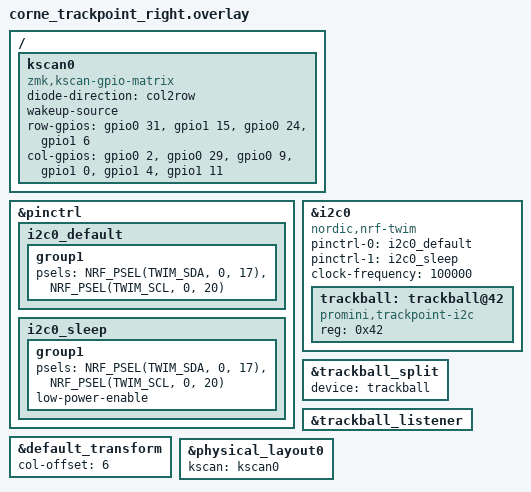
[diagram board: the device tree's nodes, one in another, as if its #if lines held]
#include "corne_trackpoint.dtsi"

&pinctrl {
    i2c0_default: i2c0_default {
        group1 {
            psels = <NRF_PSEL(TWIM_SDA, 0, 17)>,
                    <NRF_PSEL(TWIM_SCL, 0, 20)>;
        };
    };
    i2c0_sleep: i2c0_sleep {
        group1 {
            psels = <NRF_PSEL(TWIM_SDA, 0, 17)>,
                    <NRF_PSEL(TWIM_SCL, 0, 20)>;
            low-power-enable;
        };
    };
};

&i2c0 {
    compatible = "nordic,nrf-twim";
    status = "okay";
    pinctrl-0 = <&i2c0_default>;
    pinctrl-1 = <&i2c0_sleep>;
    pinctrl-names = "default", "sleep";
    clock-frequency = <100000>;

    trackball: trackball@42 {
        compatible = "promini,trackpoint-i2c";
        reg = <0x42>;
    };
};

#if defined(CONFIG_ZMK_SPLIT_ROLE_PERIPHERAL) && CONFIG_ZMK_SPLIT_ROLE_PERIPHERAL
/* Peripheral: split forwards trackball data to dongle */
&trackball_split {
    device = <&trackball>;
};
&trackball_listener {
    status = "okay";
};
#else
/* Central / standalone (no split): listener reads trackball directly + layer-toggle */
/ {
    temp_layer: temp_layer {
        compatible = "zmk,input-processor-temp-layer";
        #input-processor-cells = <2>;
        status = "okay";
    };
};

&trackball_listener {
    device = <&trackball>;
    input-processors = <&temp_layer 2 2000>;
    status = "okay";
};
#endif

&default_transform {
    col-offset = <6>;
};

&physical_layout0 {
    kscan = <&kscan0>;
};

/ {
    kscan0: kscan0 {
        compatible = "zmk,kscan-gpio-matrix";
        diode-direction = "col2row";
        wakeup-source;
        row-gpios
            = <&gpio0 31 (GPIO_ACTIVE_HIGH | GPIO_PULL_DOWN)>
            , <&gpio1 15 (GPIO_ACTIVE_HIGH | GPIO_PULL_DOWN)>
            , <&gpio0 24 (GPIO_ACTIVE_HIGH | GPIO_PULL_DOWN)>
            , <&gpio1 6  (GPIO_ACTIVE_HIGH | GPIO_PULL_DOWN)>
            ;
        col-gpios
            = <&gpio0 2  GPIO_ACTIVE_HIGH>
            , <&gpio0 29 GPIO_ACTIVE_HIGH>
            , <&gpio0 9  GPIO_ACTIVE_HIGH>
            , <&gpio1 0  GPIO_ACTIVE_HIGH>
            , <&gpio1 4  GPIO_ACTIVE_HIGH>
            , <&gpio1 11 GPIO_ACTIVE_HIGH>
            ;
    };
};
